# ISS_TOP register map
Vendor: Texas Instruments
Peripheral module from a debugger description file (folder TDA2Px).
Registers are 32-bit, access per field, reset 0x0 unless marked. A register's access mark holds for its fields unless they carry their own. Offsets are as the file gives them; lines under a group give offsets from that group; [hi:lo] are bit positions; {n}, {i} and the like mark numbered series; 'fields as' and 'values as' point back to an identical list; <NAME> marks a mode.

## ISS_TOP
0x00 ISS_HL_REVISION ro reset not defined — IP Revision Identifier (X.Y.R) Used by software to track features, bugs, and compatibility
  [31:0] REVISION — IP Revision
0x04 ISS_HL_HWINFO ro reset 0x3 — This register is reserved and users should write the reset value to this register location. Information about the IP module's hardware configuration, i.e. typically the module's HDL generics (if any). Actual field format and encoding is up to the module's designer to decide.
  [2:0] BRIDGE_BUFF — Size of the re-ordering buffer in the CCP2 read bridge.
    0=S8 (8x128-bits); 1=S16 (16x128-bits); 3=S64 (64x128-bits); 4=S128 (128x128-bits); 2=S32 (32x128-bits)
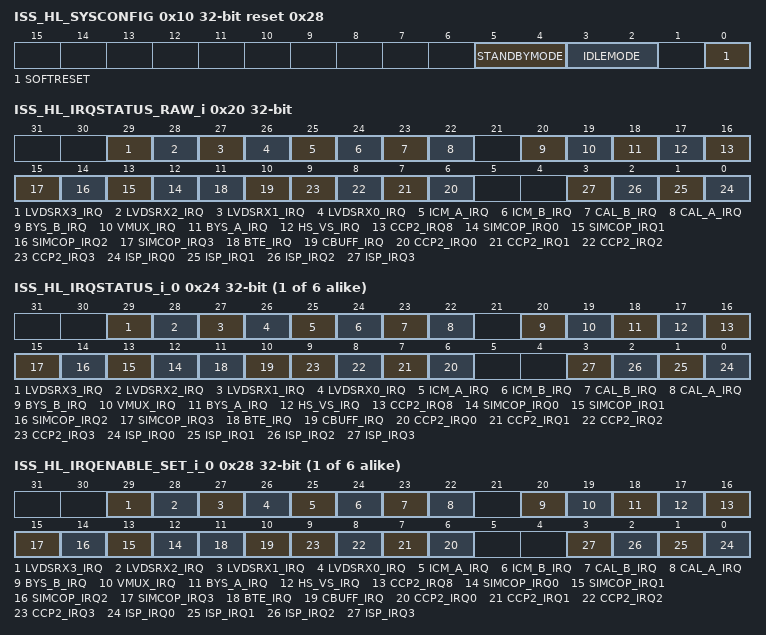
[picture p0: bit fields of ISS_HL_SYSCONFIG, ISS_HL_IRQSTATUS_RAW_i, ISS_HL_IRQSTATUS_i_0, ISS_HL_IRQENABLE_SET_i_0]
0x10 ISS_HL_SYSCONFIG reset 0x28 — Clock management configuration
  [5:4] STANDBYMODE rw — Master interface power management, standby/Wait control
    0=FORCE (Force Standby. MStandby is asserted unconditionally.); 1=NO (No Standby. MStandby is never asserted.); 3=SMART2 (Smart Standby); 2=SMART1 (Smart Standby Wakeup)
  [3:2] IDLEMODE rw — IDLE protocol configuration
    0=FORCE (Force Idle); 1=NO (No Idle); 3=SMART2 (Smart Idle); 2=SMART1 (Smart Idle)
  [0] SOFTRESET rw — Software reset.
    0=DONE (Reset done, no pending action); 1=PENDING (Reset (software or other) ongoing)
0x1C ISS_HL_IRQ_EOI — End Of Interrupt number specification
  [2:0] LINE_NUMBER rw — Software End Of Interrupt (EOI) control. Write number of interrupt output.
    {v}=EOI{v} (EOI for interrupt output line #{v}) (v=1..5); 0=READ0 (Reads always 0 (no EOI memory))
0x20 ISS_HL_IRQSTATUS_RAW_i — Per-event raw interrupt status vector, line #0. Raw status is set even if event is not enabled.
  [29] LVDSRX3_IRQ ro — Event generated by LVDSRX
    0=NOEVENT (No event pending); 1=PENDING (Event pending)
  [28] LVDSRX2_IRQ ro
  [27] LVDSRX1_IRQ ro
  [26] LVDSRX0_IRQ ro — Event generated by LVDSRX
    0=NOEVENT (No event pending); 1=PENDING (Event pending)
  [25] ICM_A_IRQ ro — This bit field is reserved and users should write the reset value to this bit location.
  [24] ICM_B_IRQ ro — This bit field is reserved and users should write the reset value to this bit location.
  [23] CAL_B_IRQ ro — Event generated by the CAL #B 0x0: No event pending 0x1: Event pending
  [22] CAL_A_IRQ ro — Event generated by the CAL #A
    0=NOEVENT (No event pending); 1=PENDING (Event pending)
  [20] BYS_B_IRQ ro — This bit field is reserved and users should write the reset value to this bit location.
  [19] VMUX_IRQ ro — Event generated by VMUX
    0=NOEVENT (No event pending); 1=PENDING (Event pending)
  [18] BYS_A_IRQ ro — This bit field is reserved and users should write the reset value to this bit location.
  [17] HS_VS_IRQ rw — HS or VS synchronization event. This event is triggered if a rising or falling edge is detected on the HS or VS signal (after the video port mux). The rising or falling edge and the HS or VS signal selection is chosen with theISS_CTRL.SYNC_DETECT bit field.
    0=NOACTION; 1=SET (Set event (debug))
  [16] CCP2_IRQ8 ro — This bit field is reserved and users should write the reset value to this bit location.
  [n+12] SIMCOP_IRQ{n} ro (n=0..3) — Event generated by SIMCOP
    0=NOEVENT (No event pending); 1=PENDING (Event pending)
  [11] BTE_IRQ ro — This bit field is reserved and users should write the reset value to this bit location.
  [10] CBUFF_IRQ ro — This bit field is reserved and users should write the reset value to this bit location.
  [n+6] CCP2_IRQ{n} ro (n=0..3) — This bit field is reserved and users should write the reset value to this bit location.
  [n] ISP_IRQ{n} ro (n=0..3) — Combined interrupt event provided by the ISP.
    0=NOEVENT (No event pending); 1=PENDING (Event pending)
{0x24+0x10*i} ISS_HL_IRQSTATUS_i_{i} (i=0..5) — Per-event 'enabled' interrupt status vector, line #0. Enabled status isn't set unless event is enabled.
  [29] LVDSRX3_IRQ ro — Event generated by LVDSRX
    0=NOEVENT (No (enabled) event pending); 1=PENDING (Event pending)
  [28] LVDSRX2_IRQ ro
  [27] LVDSRX1_IRQ ro
  [26] LVDSRX0_IRQ ro — Event generated by LVDSRX
    values as LVDSRX3_IRQ
  [25] ICM_A_IRQ ro — This bit field is reserved and users should write the reset value to this bit location.
  [24] ICM_B_IRQ ro — This bit field is reserved and users should write the reset value to this bit location.
  [23] CAL_B_IRQ ro — Event generated by CAL #B 0x0: No (enabled) event pending 0x1: Event pending
  [22] CAL_A_IRQ ro — Event generated by CAL #A
    values as LVDSRX3_IRQ
  [20] BYS_B_IRQ ro — This bit field is reserved and users should write the reset value to this bit location.
  [19] VMUX_IRQ ro — Event generated by VMUX
    values as LVDSRX3_IRQ
  [18] BYS_A_IRQ ro — This bit field is reserved and users should write the reset value to this bit location.
  [17] HS_VS_IRQ rw — HS or VS synchronization event. This event is triggered if a rising or falling edge is detected on the HS or VS signal (after the video port mux). The rising or falling edge and the HS or VS signal selection is chosen with theISS_CTRL.SYNC_DETECT bit field.
    0=NOACTION; 1=CLEAR (Clear (raw) event)
  [16] CCP2_IRQ8 ro — This bit field is reserved and users should write the reset value to this bit location.
  [n+12] SIMCOP_IRQ{n} ro (n=0..3) — Event generated by SIMCOP
    values as LVDSRX3_IRQ
  [11] BTE_IRQ ro — This bit field is reserved and users should write the reset value to this bit location.
  [10] CBUFF_IRQ ro — This bit field is reserved and users should write the reset value to this bit location.
  [n+6] CCP2_IRQ{n} ro (n=0..3) — This bit field is reserved and users should write the reset value to this bit location.
  [n] ISP_IRQ{n} ro (n=0..3) — Combined interrupt event provided by the ISP.
    values as LVDSRX3_IRQ
{0x28+0x10*i} ISS_HL_IRQENABLE_SET_i_{i} (i=0..5) — Per-event interrupt enable bit vector Write 1 to set (enable interrupt). Readout equal to corresponding _CLR register.
  [29] LVDSRX3_IRQ rw — Event generated by LVDSRX
    0=NOACTION; 1=ENABLE (Enable interrupt)
  [28] LVDSRX2_IRQ ro
  [27] LVDSRX1_IRQ ro
  [26] LVDSRX0_IRQ rw — Event generated by LVDSRX
    0=NOACTION; 1=ENABLE (Enable interrupt)
  [25] ICM_A_IRQ ro — This bit field is reserved and users should write the reset value to this bit location.
  [24] ICM_B_IRQ ro — This bit field is reserved and users should write the reset value to this bit location.
  [23] CAL_B_IRQ ro — Event generated by CAL #B 0x0: No action 0x1: Enable interrupt
  [22] CAL_A_IRQ rw — Event generated by CAL #A
    0=NOACTION; 1=ENABLE (Enable interrupt)
  [20] BYS_B_IRQ ro — This bit field is reserved and users should write the reset value to this bit location.
  [19] VMUX_IRQ rw — Event generated by VMUX
    0=NOACTION; 1=ENABLE (Enable interrupt)
  [18] BYS_A_IRQ ro — This bit field is reserved and users should write the reset value to this bit location.
  [17] HS_VS_IRQ rw — HS or VS synchronization event. This event is triggered if a rising or falling edge is detected on the HS or VS signal (after the video port mux). The rising or falling edge and the HS or VS signal selection is chosen with theISS_CTRL.SYNC_DETECT bit field.
    0=NOACTION; 1=ENABLE (Enable interrupt)
  [16] CCP2_IRQ8 ro — This bit field is reserved and users should write the reset value to this bit location.
  [n+12] SIMCOP_IRQ{n} rw (n=0..3) — Event generated by SIMCOP
    0=NOACTION; 1=ENABLE (Enable interrupt)
  [11] BTE_IRQ ro — This bit field is reserved and users should write the reset value to this bit location.
  [10] CBUFF_IRQ ro — This bit field is reserved and users should write the reset value to this bit location.
  [n+6] CCP2_IRQ{n} ro (n=0..3) — This bit field is reserved and users should write the reset value to this bit location.
  [n] ISP_IRQ{n} rw (n=0..3) — Combined interrupt event provided by the ISP.
    0=NOACTION; 1=ENABLE (Enable interrupt)
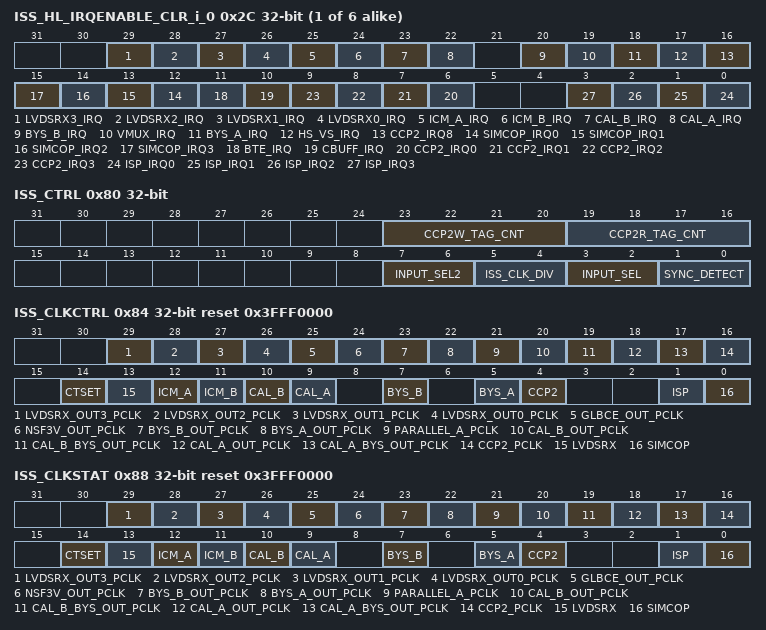
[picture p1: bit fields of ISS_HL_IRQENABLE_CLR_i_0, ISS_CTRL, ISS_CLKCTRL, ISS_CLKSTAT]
{0x2C+0x10*i} ISS_HL_IRQENABLE_CLR_i_{i} (i=0..5) — Per-event interrupt enable bit vector Write 1 to clear (disable interrupt). Readout equal to corresponding _SET register.
  [29] LVDSRX3_IRQ rw — Event generated by LVDSRX
    0=NOACTION; 1=DISABLE (Disable interrupt)
  [28] LVDSRX2_IRQ ro
  [27] LVDSRX1_IRQ ro
  [26] LVDSRX0_IRQ rw — Event generated by LVDSRX
    0=NOACTION; 1=DISABLE (Disable interrupt)
  [25] ICM_A_IRQ ro — This bit field is reserved and users should write the reset value to this bit location.
  [24] ICM_B_IRQ ro — This bit field is reserved and users should write the reset value to this bit location.
  [23] CAL_B_IRQ ro — Event generated by CAL #B 0x0: No action 0x1: Disable interrupt
  [22] CAL_A_IRQ rw — Event generated by CAL #A
    0=NOACTION; 1=DISABLE (Disable interrupt)
  [20] BYS_B_IRQ ro — This bit field is reserved and users should write the reset value to this bit location.
  [19] VMUX_IRQ rw — Event generated by VMUX
    0=NOACTION; 1=DISABLE (Disable interrupt)
  [18] BYS_A_IRQ ro — This bit field is reserved and users should write the reset value to this bit location.
  [17] HS_VS_IRQ rw — HS or VS synchronization event. This event is triggered if a rising or falling edge is detected on the HS or VS signal (after the video port mux). The rising or falling edge and the HS or VS signal selection is chosen with theISS_CTRL.SYNC_DETECT bit field.
    0=NOACTION; 1=DISABLE (Disable interrupt)
  [16] CCP2_IRQ8 ro — This bit field is reserved and users should write the reset value to this bit location.
  [n+12] SIMCOP_IRQ{n} rw (n=0..3) — Event generated by SIMCOP
    0=NOACTION; 1=DISABLE (Disable interrupt)
  [11] BTE_IRQ ro — This bit field is reserved and users should write the reset value to this bit location.
  [10] CBUFF_IRQ ro — This bit field is reserved and users should write the reset value to this bit location.
  [n+6] CCP2_IRQ{n} ro (n=0..3) — This bit field is reserved and users should write the reset value to this bit location.
  [n] ISP_IRQ{n} rw (n=0..3) — Combined interrupt event provided by the ISP.
    0=NOACTION; 1=DISABLE (Disable interrupt)
0x80 ISS_CTRL — ISS control register
  [23:20] CCP2W_TAG_CNT rw — This bit field is reserved and users should write the reset value to this bit location. Defines the maximum number of tags that could be used by the CCP2 write bridge
  [19:16] CCP2R_TAG_CNT rw — This bit field is reserved and users should write the reset value to this bit location. Defines the maximum number of tags that could be used by the CCP2 read bridge
  [7:6] INPUT_SEL2 rw — This bit field is reserved and users should write the reset value to this bit location. Selects ISP input. Legacy only. Use video mux instead.
    0=NONE (Input selected by the INPUT_SEL register); 2=CSI3_A
  [5:4] ISS_CLK_DIV rw — ISS functional clock division CLK refers to the input clock provided to the ISS FCLK is the functional clock provided to ISS top level and sub modules CFGCLK is the clock used for the configuration network
    0=NONE (FCLK=CLK CFGCLK=CLK/2); 1=DIV2 (FCLK=CLK/2 CFGCLK=CLK/4); 3=RSZ (Reserved); 2=DIV4 (FCLK=CLK/4 CFGCLK=CLK/8)
  [3:2] INPUT_SEL rw — This bit field is reserved and users should write the reset value to this bit location. Selects ISP input. Perserved for legacy only. Use video mux for new SW.
    3=PAR (Parallel interface); 2=CCP2
  [1:0] SYNC_DETECT rw — Chooses among rising and falling edge for the HS_VS_IRQ synchronization event
    0=HSF (HS falling edge); 1=HSR (HS raising edge); 3=VSR (VS raising edge); 2=VSF (VS falling edge)
0x84 ISS_CLKCTRL reset 0x3FFF0000 — ISS clock control register. Use to enable/disable the interface and functional clock of ISS sub-modules.
  [29] LVDSRX_OUT3_PCLK rw — Enables the pixel clock at VMUX input level.
    0=ZERO (Disabled); 1=ONE (Enabled)
  [28] LVDSRX_OUT2_PCLK rw — This bit field is reserved and users should write the reset value to this bit location. Enables the pixel clock at VMUX input level.
    0=ZERO (Disabled); 1=ONE (Enabled)
  [27] LVDSRX_OUT1_PCLK rw — This bit field is reserved and users should write the reset value to this bit location. Enables the pixel clock at VMUX input level.
    0=ZERO (Disabled); 1=ONE (Enabled)
  [26] LVDSRX_OUT0_PCLK rw — Enables the pixel clock at VMUX input level.
    0=ZERO (Disabled); 1=ONE (Enabled)
  [25] GLBCE_OUT_PCLK rw — Enables the pixel clock at VMUX input level.
    0=ZERO (Disabled); 1=ONE (Enabled)
  [24] NSF3V_OUT_PCLK rw — Enables the pixel clock at VMUX input level.
    0=ZERO (Disabled); 1=ONE (Enabled)
  [23] BYS_B_OUT_PCLK rw — This bit field is reserved and users should write the reset value to this bit location. Enables the pixel clock at VMUX input level.
    0=ZERO (Disabled); 1=ONE (Enabled)
  [22] BYS_A_OUT_PCLK rw — This bit field is reserved and users should write the reset value to this bit location. Enables the pixel clock at VMUX input level.
    0=ZERO (Disabled); 1=ONE (Enabled)
  [21] PARALLEL_A_PCLK rw — Enables the pixel clock at VMUX input level.
    0=ZERO (Disabled); 1=ONE (Enabled)
  [20] CAL_B_OUT_PCLK rw — Enables the pixel clock at VMUX input level.
    0=ZERO (Disabled); 1=ONE (Enabled)
  [19] CAL_B_BYS_OUT_PCLK rw — Enables the pixel clock at VMUX input level.
    0=ZERO (Disabled); 1=ONE (Enabled)
  [18] CAL_A_OUT_PCLK rw — Enables the pixel clock at VMUX input level.
    0=ZERO (Disabled); 1=ONE (Enabled)
  [17] CAL_A_BYS_OUT_PCLK rw — Enables the pixel clock at VMUX input level.
    0=ZERO (Disabled); 1=ONE (Enabled)
  [16] CCP2_PCLK rw — This bit field is reserved and users should write the reset value to this bit location. Enables the pixel clock at VMUX input level.
    0=ZERO (Disabled); 1=ONE (Enabled)
  [14] CTSET wo
    0=OFF (Request shutdown of the sub-module. No effect if the sub-module clock is already off.); 1=ON (Request enable of the sub-module. No effect if the sub-module clock is already on.)
  [13] LVDSRX wo
    values as CTSET
  [12] ICM_A wo — This bit field is reserved and users should write the reset value to this bit location. ICM #A
    values as CTSET
  [11] ICM_B wo — This bit field is reserved and users should write the reset value to this bit location. ICM #B
    values as CTSET
  [10] CAL_B wo
    values as CTSET
  [9] CAL_A wo
    values as CTSET
  [7] BYS_B wo — This bit field is reserved and users should write the reset value to this bit location. Bayer scaler #B
    values as CTSET
  [5] BYS_A wo — This bit field is reserved and users should write the reset value to this bit location. Bayer scaler #A
    values as CTSET
  [4] CCP2 wo — This bit field is reserved and users should write the reset value to this bit location. CCP2
    values as CTSET
  [1] ISP wo
    values as CTSET
  [0] SIMCOP wo
    values as CTSET
0x88 ISS_CLKSTAT ro reset 0x3FFF0000 — ISS clock status register.
  [all] fields
    0=OFF (The sub-module is off); 1=ON (The sub-module is on)
  [29] LVDSRX_OUT3_PCLK — Status of the pixel clock
  [28] LVDSRX_OUT2_PCLK — This bit field is reserved and users should write the reset value to this bit location. Status of the pixel clock
  [27] LVDSRX_OUT1_PCLK — This bit field is reserved and users should write the reset value to this bit location. Status of the pixel clock
  [26] LVDSRX_OUT0_PCLK — Status of the pixel clock
  [25] GLBCE_OUT_PCLK — Status of the pixel clock
  [24] NSF3V_OUT_PCLK — Status of the pixel clock
  [23] BYS_B_OUT_PCLK — This bit field is reserved and users should write the reset value to this bit location. Status of the pixel clock
  [22] BYS_A_OUT_PCLK — This bit field is reserved and users should write the reset value to this bit location. Status of the pixel clock
  [21] PARALLEL_A_PCLK — Status of the pixel clock
  [20] CAL_B_OUT_PCLK — Status of the pixel clock
  [19] CAL_B_BYS_OUT_PCLK — Status of the pixel clock
  [18] CAL_A_OUT_PCLK — Status of the pixel clock
  [17] CAL_A_BYS_OUT_PCLK — Status of the pixel clock
  [16] CCP2_PCLK — This bit field is reserved and users should write the reset value to this bit location. Status of the pixel clock
  [14] CTSET
  [13] LVDSRX
  [12] ICM_A — This bit field is reserved and users should write the reset value to this bit location. ICM #A
  [11] ICM_B — This bit field is reserved and users should write the reset value to this bit location. ICM #B
  [10] CAL_B
  [9] CAL_A
  [7] BYS_B — This bit field is reserved and users should write the reset value to this bit location. Bayer scaler #B
  [5] BYS_A — This bit field is reserved and users should write the reset value to this bit location. Bayer scaler #A
  [4] CCP2 — This bit field is reserved and users should write the reset value to this bit location. CCP2
  [1] ISP
  [0] SIMCOP
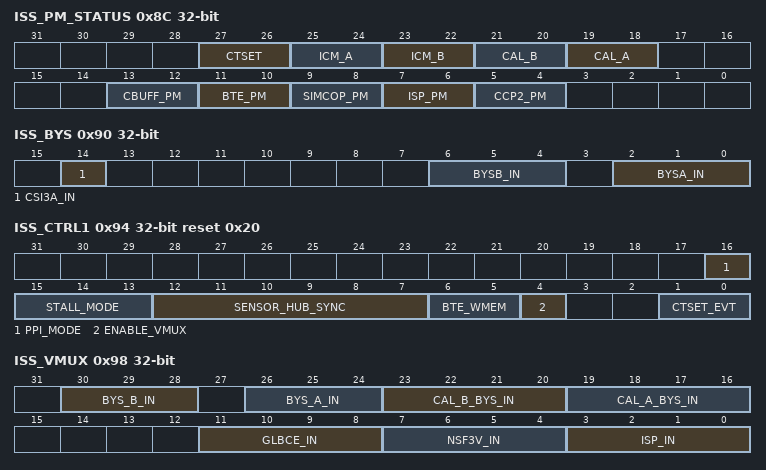
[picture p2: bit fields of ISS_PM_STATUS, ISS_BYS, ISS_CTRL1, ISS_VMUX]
0x8C ISS_PM_STATUS ro — ISS power manager status register. SW could know what modules are in functional or STANDBY/IDLE state. This feature could be particulaly useful to debug when ISS doesn't go into STANDBY mode
  [27:26] CTSET — Power status of the CTSET module
    0=STANDBY; 1=TRANS (Transition); 2=FUNC (Functional)
  [25:24] ICM_A — This bit field is reserved and users should write the reset value to this bit location. Power status of the ICM #A module
    0=STANDBY; 1=TRANS (Transition); 2=FUNC (Functional)
  [23:22] ICM_B — This bit field is reserved and users should write the reset value to this bit location. Power status of the ICM #B module
    0=STANDBY; 1=TRANS (Transition); 2=FUNC (Functional)
  [21:20] CAL_B — Power status of the CAL #B module
    0=STANDBY; 1=TRANS (Transition); 2=FUNC (Functional)
  [19:18] CAL_A — Power status of the CAL #A module
    0=STANDBY; 1=TRANS (Transition); 2=FUNC (Functional)
  [13:12] CBUFF_PM — This bit field is reserved and users should write the reset value to this bit location. Power status of the CBUFF module
    0=IDLE; 1=TRANS (Transition); 2=FUNC (Functional)
  [11:10] BTE_PM — This bit field is reserved and users should write the reset value to this bit location. Power status of the BTE module
    0=IDLE; 1=TRANS (Transition); 2=FUNC (Functional)
  [9:8] SIMCOP_PM — Power status of the SIMCOP module
    0=STANDBY; 1=TRANS (Transition); 2=FUNC (Functional)
  [7:6] ISP_PM — Power status of the ISP module
    0=STANDBY; 1=TRANS (Transition); 2=FUNC (Functional)
  [5:4] CCP2_PM — This bit field is reserved and users should write the reset value to this bit location. Power status of the CCP2 module
    0=STANDBY; 1=TRANS (Transition); 2=FUNC (Functional)
0x90 ISS_BYS — This register is reserved and users should write the reset value to this register location. BYS IO selection. Legacy only. Use video mux for new SW
  [14] CSI3A_IN rw — This bit field is reserved and users should write the reset value to this bit location. Selects input of CSI-3 #A BYS input
    0=A (BYS #A); 1=B (BYS #B)
  [6:4] BYSB_IN rw — This bit field is reserved and users should write the reset value to this bit location. Selects BYS input
    0=NONE (Disabled); 4=CSI3_A
  [2:0] BYSA_IN rw — This bit field is reserved and users should write the reset value to this bit location. Selects BYS input
    0=NONE (Disabled); 4=CSI3_A
0x94 ISS_CTRL1 reset 0x20 — ISS control register
  [16] PPI_MODE rw — Controls PPI interface - CAL mux at ISS level. CSI-2 #B
    0=BALANCED (CSI-2 #A -- CAL #A-1 CSI-2 #B -- CAL #B-1 CSI-2 #C -- CAL #A-0 CSI-3 #D -- CAL #B-0); 1=EXTENDED (CSI-2 #A -- CAL #A-1 CSI-2 #B -- CAL #A-0 CSI-2 #C -- CAL #B-1 CSI-3 #D -- CAL #B-0)
  [15:13] STALL_MODE rw — Refer to the functional specification for details.
  [12:7] SENSOR_HUB_SYNC rw — This bit field is reserved and users should write the reset value to this bit location. Selects which syn event to export to the sensor hub. Refer to the functional specification for details
  [6:5] BTE_WMEM rw — This bit field is reserved and users should write the reset value to this bit location. Defines how much ISS-SL2 is attached to BTE as working memory
    0=ZERO (BTE has no working memory and can't be used); 1=ONE (Complete ISS-SL2 used as BTE working memory)
  [4] ENABLE_VMUX rw — Enables the video mux instead of legacy mode for ISP #A input and BYS connections. Other VMUX settings are not affected.
    0=LEGACY (Legacy mode. ISP input is defined by.INPUT_SEL and .INPUT_SEL2 BYS connections are defined by the register.); 1=VMUX (ISP #A and BYS connections are controlled by the register. That's the preferred mode for ADASL)
  [1:0] CTSET_EVT rw — CTSET event selection. Refer to functional spec for details
0x98 ISS_VMUX — ISS video mux control
  [30:28] BYS_B_IN rw — This bit field is reserved and users should write the reset value to this bit location. Data source connected to BYS #B
    1=CAL_A_BYS_OUT; 0=ZERO (tied to 0); 2=CAL_B_BYS_OUT; 4=LVDSRX_OUT3; 3=LVDSRX_OUT1
  [26:24] BYS_A_IN rw — This bit field is reserved and users should write the reset value to this bit location. Data source connected to BYS #A
    1=CAL_A_BYS_OUT; 0=ZERO (tied to 0); 2=CAL_B_BYS_OUT; 4=LVDSRX_OUT2; 3=LVDSRX_OUT0
  [23:20] CAL_B_BYS_IN rw — This bit field is reserved and users should write the reset value to this bit location. BData source connected to the BYSin port of CAL #A
    1=BYS_A_OUT; 0=ZERO (tied to 0); 2=BYS_B_OUT; 8=LDVSRX_OUT3 (LVDSRX out3); 4=GLBCE_OUT; 5=LVDSRX_OUT1; 3=NSF3V_OUT
  [19:16] CAL_A_BYS_IN rw — Data source connected to the BYSin port of CAL #A
    6=LVDSRX_OUT3; 1=BYS_A_OUT (Reserved BYS #A out); 0=ZERO (tied to 0); 2=BYS_B_OUT (Reserved BYS #B out); 8=LVDSRX_OUT2 (Reserved LVDSRX out2); 4=GLBCE_OUT; 5=LVDSRX_OUT0; 3=NSF3V_OUT
  [11:8] GLBCE_IN rw — Data source connected to GLBCE
    0=ZERO (tied to 0); 1=CAL_A_BYS_OUT (CAL #A out); 2=CAL_B_BYS_OUT (Reserved CAL #B out)
  [7:4] NSF3V_IN rw — Data source connected to NSF3V
    values as GLBCE_IN
  [3:0] ISP_IN rw — Data source connected to ISP
    6=LVDSRX_OUT2 (Reserved LVDSRX out 2); 1=CAL_A_OUT; 7=LVDSRX_OUT3; 0=ZERO (tied to 0); 2=CAL_B_OUT (Reserved CAL #B out); 8=CCP2 (Reserved CCP2 out); 4=LVDSRX_OUT0; 5=LVDSRX_OUT1 (Reserved LVDSRX out 1); 3=PARALLEL_A (Parallel interface #A)
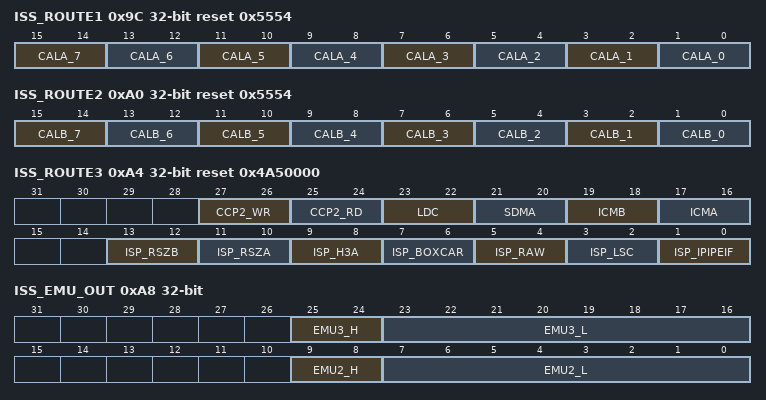
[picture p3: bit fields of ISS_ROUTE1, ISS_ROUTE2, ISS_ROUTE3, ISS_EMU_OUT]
0x9C ISS_ROUTE1 reset 0x5554 — Controls traffic routing inside ISS
  [all] fields
    0=OCPM2; 1=OCPM1; 2=OCPM3
  [2n+1:2n] CALA_{n} rw (n=1..7) — CPort #{n}
  [1:0] CALA_0 rw — CPort #0. Only used for RD DMA / non RT traffic
0xA0 ISS_ROUTE2 reset 0x5554 — This register is reserved and users should write the reset value to this register location.Controls traffic routing inside ISS
  [all] fields
    0=OCPM2; 1=OCPM1; 2=OCPM3
  [2n+1:2n] CALB_{n} rw (n=1..7) — CPort #{n}
  [1:0] CALB_0 rw — CPort #0. Only used for RD DMA / non RT traffic
0xA4 ISS_ROUTE3 reset 0x4A50000 — Controls traffic routing inside ISS
  [all] fields
    0=OCPM2; 1=OCPM1; 2=OCPM3
  [27:26] CCP2_WR rw — This bit field is reserved and users should write the reset value to this bit location. CCP2 WR
  [25:24] CCP2_RD rw — This bit field is reserved and users should write the reset value to this bit location. CCP2 RD
  [23:22] LDC rw — SIMCOP LDC
  [21:20] SDMA rw — SIMCOP - DMA
  [19:18] ICMB rw — This bit field is reserved and users should write the reset value to this bit location. ICM B
  [17:16] ICMA rw — This bit field is reserved and users should write the reset value to this bit location. ICM A
  [13:12] ISP_RSZB rw
  [11:10] ISP_RSZA rw
  [9:8] ISP_H3A rw
  [7:6] ISP_BOXCAR rw
  [5:4] ISP_RAW rw
  [3:2] ISP_LSC rw
  [1:0] ISP_IPIPEIF rw — IPIPEIF
0xA8 ISS_EMU_OUT — Select exported ISS level events
  [25:24] EMU3_H rw, [23:16] EMU3_L rw, [9:8] EMU2_H rw, [7:0] EMU2_L rw
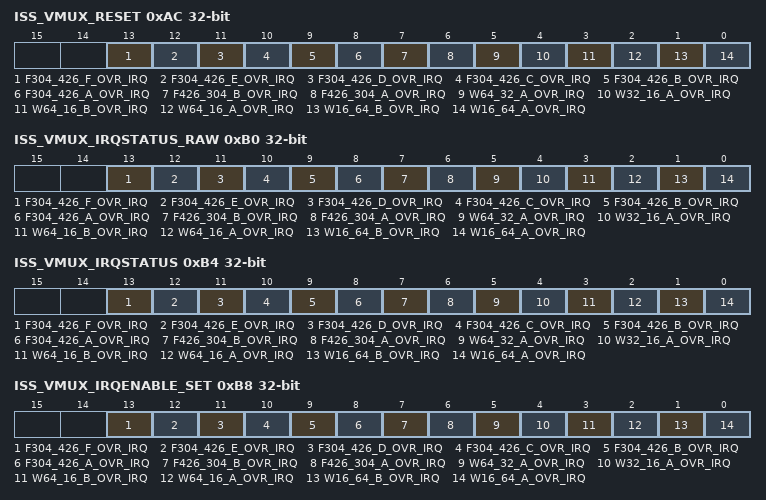
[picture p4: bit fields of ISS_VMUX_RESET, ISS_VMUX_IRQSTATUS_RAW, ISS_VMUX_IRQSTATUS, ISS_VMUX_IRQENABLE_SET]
0xAC ISS_VMUX_RESET — For debug purposes only. Resets the state of individual FIFOs in the video mux.
  [all] fields
    0=NOEFFECT; 1=RESET
  [13] F304_426_F_OVR_IRQ wo
  [12] F304_426_E_OVR_IRQ wo
  [11] F304_426_D_OVR_IRQ wo
  [10] F304_426_C_OVR_IRQ wo
  [9] F304_426_B_OVR_IRQ wo
  [8] F304_426_A_OVR_IRQ wo
  [7] F426_304_B_OVR_IRQ wo
  [6] F426_304_A_OVR_IRQ wo
  [5] W64_32_A_OVR_IRQ wo
  [4] W32_16_A_OVR_IRQ wo
  [3] W64_16_B_OVR_IRQ wo
  [2] W64_16_A_OVR_IRQ wo
  [1] W16_64_B_OVR_IRQ wo
  [0] W16_64_A_OVR_IRQ wo
0xB0 ISS_VMUX_IRQSTATUS_RAW — Per-event raw interrupt status vector. Raw status is set even if event is not enabled.
  [13] F304_426_F_OVR_IRQ ro
  [12] F304_426_E_OVR_IRQ ro
  [11] F304_426_D_OVR_IRQ ro
  [10] F304_426_C_OVR_IRQ ro
  [9] F304_426_B_OVR_IRQ ro
  [8] F304_426_A_OVR_IRQ ro
  [7] F426_304_B_OVR_IRQ ro
  [6] F426_304_A_OVR_IRQ ro
  [5] W64_32_A_OVR_IRQ rw
    0=NOACTION; 1=SET (Set event (debug))
  [4] W32_16_A_OVR_IRQ rw
    0=NOACTION; 1=SET (Set event (debug))
  [3] W64_16_B_OVR_IRQ rw
    0=NOACTION; 1=SET (Set event (debug))
  [2] W64_16_A_OVR_IRQ rw
    0=NOACTION; 1=SET (Set event (debug))
  [1] W16_64_B_OVR_IRQ rw
    0=NOACTION; 1=SET (Set event (debug))
  [0] W16_64_A_OVR_IRQ rw
    0=NOACTION; 1=SET (Set event (debug))
0xB4 ISS_VMUX_IRQSTATUS — Per-event 'enabled' interrupt status vector. Enabled status isn't set unless event is enabled.
  [13] F304_426_F_OVR_IRQ ro
  [12] F304_426_E_OVR_IRQ ro
  [11] F304_426_D_OVR_IRQ ro
  [10] F304_426_C_OVR_IRQ ro
  [9] F304_426_B_OVR_IRQ ro
  [8] F304_426_A_OVR_IRQ ro
  [7] F426_304_B_OVR_IRQ ro
  [6] F426_304_A_OVR_IRQ ro
  [5] W64_32_A_OVR_IRQ rw
    0=NOACTION; 1=CLEAR (Clear (raw) event)
  [4] W32_16_A_OVR_IRQ rw
    0=NOACTION; 1=CLEAR (Clear (raw) event)
  [3] W64_16_B_OVR_IRQ rw
    0=NOACTION; 1=CLEAR (Clear (raw) event)
  [2] W64_16_A_OVR_IRQ rw
    0=NOACTION; 1=CLEAR (Clear (raw) event)
  [1] W16_64_B_OVR_IRQ rw
    0=NOACTION; 1=CLEAR (Clear (raw) event)
  [0] W16_64_A_OVR_IRQ rw
    0=NOACTION; 1=CLEAR (Clear (raw) event)
0xB8 ISS_VMUX_IRQENABLE_SET — Per-event interrupt enable bit vector Write 1 to set (enable interrupt). Readout equal to corresponding _CLR register.
  [13] F304_426_F_OVR_IRQ ro
  [12] F304_426_E_OVR_IRQ ro
  [11] F304_426_D_OVR_IRQ ro
  [10] F304_426_C_OVR_IRQ ro
  [9] F304_426_B_OVR_IRQ ro
  [8] F304_426_A_OVR_IRQ ro
  [7] F426_304_B_OVR_IRQ ro
  [6] F426_304_A_OVR_IRQ ro
  [5] W64_32_A_OVR_IRQ rw
    0=NOACTION; 1=ENABLE (Enable interrupt)
  [4] W32_16_A_OVR_IRQ rw
    0=NOACTION; 1=ENABLE (Enable interrupt)
  [3] W64_16_B_OVR_IRQ rw
    0=NOACTION; 1=ENABLE (Enable interrupt)
  [2] W64_16_A_OVR_IRQ rw
    0=NOACTION; 1=ENABLE (Enable interrupt)
  [1] W16_64_B_OVR_IRQ rw
    0=NOACTION; 1=ENABLE (Enable interrupt)
  [0] W16_64_A_OVR_IRQ rw
    0=NOACTION; 1=ENABLE (Enable interrupt)
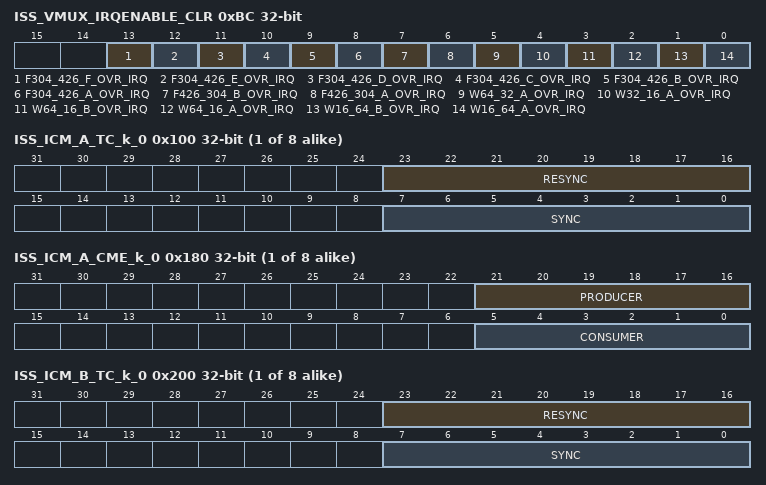
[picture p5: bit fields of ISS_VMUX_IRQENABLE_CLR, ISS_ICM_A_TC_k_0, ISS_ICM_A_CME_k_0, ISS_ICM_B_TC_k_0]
0xBC ISS_VMUX_IRQENABLE_CLR — Per-event interrupt enable bit vector Write 1 to clear (disable interrupt). Readout equal to corresponding _SET register.
  [13] F304_426_F_OVR_IRQ ro
  [12] F304_426_E_OVR_IRQ ro
  [11] F304_426_D_OVR_IRQ ro
  [10] F304_426_C_OVR_IRQ ro
  [9] F304_426_B_OVR_IRQ ro
  [8] F304_426_A_OVR_IRQ ro
  [7] F426_304_B_OVR_IRQ ro
  [6] F426_304_A_OVR_IRQ ro
  [5] W64_32_A_OVR_IRQ rw
    0=NOACTION; 1=DISABLE (Disable interrupt)
  [4] W32_16_A_OVR_IRQ rw
    0=NOACTION; 1=DISABLE (Disable interrupt)
  [3] W64_16_B_OVR_IRQ rw
    0=NOACTION; 1=DISABLE (Disable interrupt)
  [2] W64_16_A_OVR_IRQ rw
    0=NOACTION; 1=DISABLE (Disable interrupt)
  [1] W16_64_B_OVR_IRQ rw
    0=NOACTION; 1=DISABLE (Disable interrupt)
  [0] W16_64_A_OVR_IRQ rw
    0=NOACTION; 1=DISABLE (Disable interrupt)
{0x100+0x10*i} ISS_ICM_A_TC_k_{i} (i=0..7) — This register is reserved and users should write the reset value to this register location. Select ISS level event that triggers TC
  [23:16] RESYNC rw — ID of the frame resynchronization event
  [7:0] SYNC rw — ID of the transfer trigger event
{0x180+0x10*i} ISS_ICM_A_CME_k_{i} (i=0..7) — This register is reserved and users should write the reset value to this register location. Selects P_START/ P_DONE and C_START / C_DONE pair mapping to TC
  [21:16] PRODUCER rw — P_START / P_DONE
  [5:0] CONSUMER rw — C_START / C_DONE
{0x200+0x10*i} ISS_ICM_B_TC_k_{i} (i=0..7) — This register is reserved and users should write the reset value to this register location. Select ISS level event that triggers TC
  fields as ISS_ICM_A_TC_k_0
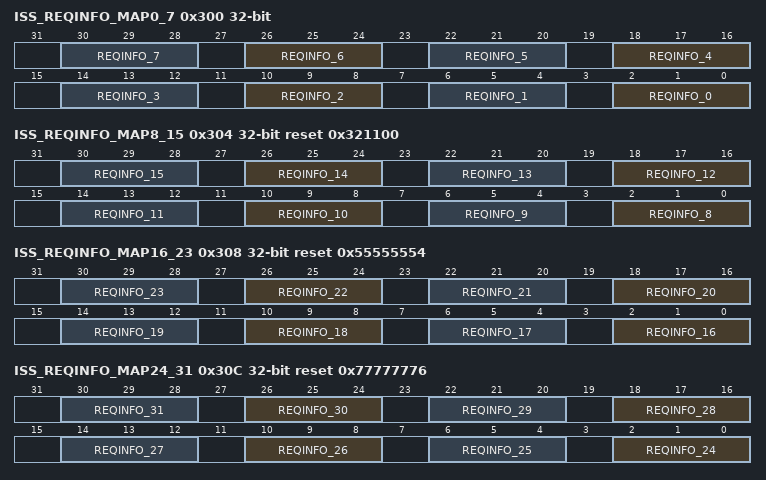
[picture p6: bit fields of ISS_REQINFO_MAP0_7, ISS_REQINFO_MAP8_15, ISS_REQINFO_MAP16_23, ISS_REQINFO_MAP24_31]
0x300 ISS_REQINFO_MAP0_7 — MReqInfo remapping table
  [4n+2:4n] REQINFO_{n} rw (n=0..7) — MReqInfo value visible @ ISS boundary
0x304 ISS_REQINFO_MAP8_15 reset 0x321100 — MReqInfo remapping table
  [4n-30:4n-32] REQINFO_{n} rw (n=8..15) — MReqInfo value visible @ ISS boundary
0x308 ISS_REQINFO_MAP16_23 reset 0x55555554 — MReqInfo remapping table
  [4n-62:4n-64] REQINFO_{n} rw (n=16..23) — MReqInfo value visible @ ISS boundary
0x30C ISS_REQINFO_MAP24_31 reset 0x77777776 — MReqInfo remapping table
  [4n-94:4n-96] REQINFO_{n} rw (n=24..31) — MReqInfo value visible @ ISS boundary
